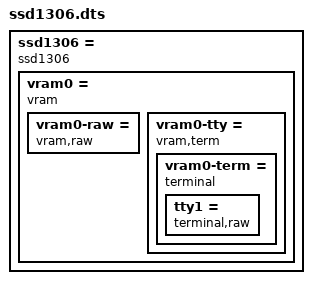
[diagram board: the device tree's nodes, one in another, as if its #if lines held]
/**
 * Copyright (C) 2022 Jan Nowotsch
 * Author Jan Nowotsch	<jan.nowotsch@gmail.com>
 *
 * Released under the terms of the GNU GPL v2.0
 */



#include <config/config.h>
#include <ssd1306.dts>
#include <term.dts>
#include <vram.dts>


ssd1306 = {
	compatible = "ssd1306";

	ssd1306_dtd(
		60			// slave address
	)

	vram0 = {
		compatible = "vram";

		vram_cfg_t(
			64,		// height
			128,	// width
			0x10,	// contrast
			0x07,	// flags (DSPFL_MIRROR_VERT | DSPFL_MIRROR_HOR | DSPFL_ORIEN_HOR)
			100		// refresh_ms
		)

#ifdef CONFIG_VRAM_RAW
		vram0-raw = {
			compatible = "vram,raw";

		};
#endif // CONFIG_VRAM_RAW

#ifdef CONFIG_VRAM_TERM
		vram0-tty = {
			compatible = "vram,term";

			vram0-term = {
				compatible = "terminal";

				term_cfg_t(
					0x0,	// iflags (none)
					0x2,	// oflags (TOFL_NLCR)
					0x1e,	// lflags (TLFL_CURSOR | TLFL_SCROLL | TLFL_WRAP | TLFL_CANON)
					4		// tabs
				)

				tty1 = {
					compatible = "terminal,raw";
				};
			};
		};
#endif // CONFIG_VRAM_TERM
	};
};
